# ECM3532 register map
Vendor: EtaCompute; Series: ECM35xx; File version: 1.0.0
CPU: CM3 r1p1, little endian, MPU, no FPU, 3 interrupt priority bits
Registers are 32-bit, read-write, reset 0x0 unless marked. A register's access mark holds for its fields unless they carry their own. Offsets are from the block's base; [hi:lo] are bit positions.

## ADC — The ADC AHB interface provides programming control of the analog to digital converter.
Base 0x50050000
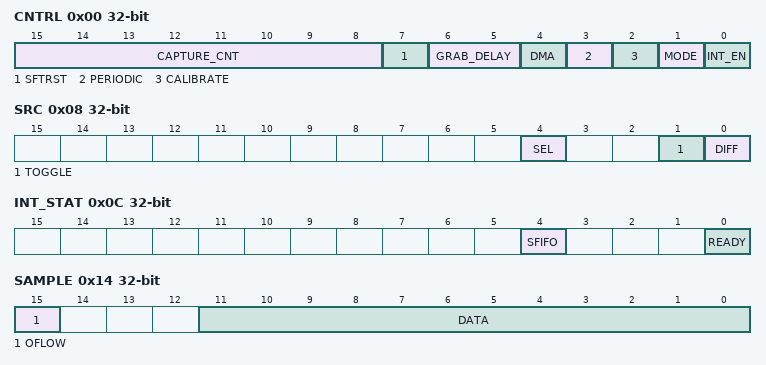
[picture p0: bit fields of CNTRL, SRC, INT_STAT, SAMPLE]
0x00 CNTRL — This register provides configuration control and status information for the ADC.
  [15:8] CAPTURE_CNT — Count for time to wait while the sample and hold circuit is sampling the signal before the conversion is started. WHile the counter continues, the trigger signal will be held low. This counter runs on a 1MHz clock.
  [7] SFTRST wo — Write a once to this bit to force a soft reset to this block.
  [6:5] GRAB_DELAY — This bit field controls whent the data from the ADC is grabbed and used.
    0=IMMED (No delay added); 1=1CLK (Delay by 1 additonal clock.); 2=2CLK (Delay by 2 additonal clocks.); 3=3CLK (Delay by 3 additonal clocks.)
  [4] DMA — Set this bit to one to enable the transfer of data over to the DSP for DMA access.
    0=DISABLE (No DSP transfers are generated.); 1=ENABLE (DSP transfers are generated.)
  [3] PERIODIC — Set this bit to one to enable periodic sampling instead of firmware triggered one shot samples.
    0=DISABLE (No periodic clock selected. Use firmware trigger register.); 1=ENABLE (Use selected periodic clock from input port to trigger a conversion cycle.)
  [2] CALIBRATE — Set to one to enable calibration mode. Essentilly the differential inputs are tied together so that the offset voltage as expressed a digital ADC count can be measure by firmware. A number of conversions should be performed and the results should be averaged. NOTE: once the calibration offset has been measured, the computed value is subtracted from each successive sample after firmware reads the value in from the ADC. This is accomplished by writing the average offset value to the OFFSET register. Hardware performs a saturated add of the offset. A further NOTE, the calibration controls are ahead of the sample and hold circuit so turn it off before attempting to capture any input into the sample and hold that you intend to convert and use.
    0=OFF (Calibration mode disabled. This is the normal operating mode.); 1=ON (Calibration mode on. Essentially the differential inputs are shorted together to measure offset voltage.)
  [1] MODE — Set to one to enable the the ADC to operate and perform captures and conversions. Set to zero to disable this block.
    0=SLEEP (ADC interface disabled and in lowest power state. NOTE the ADC voltage plain may still be on.); 1=RUN (Enable the normal operation of the ADC block.)
  [0] INT_EN — Set to one to enable interrupts to the NVIC. Interrupts will then be asserted when INT_STAT is a one.
    0=DISABLE (ADC interrupts are disabled and can't reach the NVIC.); 1=ENABLE (ADC interrupts are enabled and if they occur they will be routed to the NVIC.)
0x04 CLOCK_DIV — Clock divider register.
  [19:0] VALUE — Divider for the 1 MHz input clock. When the divider count reaches zero, it is reloaded and an ADC conversion is triggered.
0x08 SRC — This register controls the source mux and differential configurations for the ADC.
  [4] SEL — Sets the channel selector for the analog mux.
    0=CHAN0 (Channel #0); 1=CHAN1 (Channel #1)
  [1] TOGGLE — Selects the analog channel based on the state of the ADC TOGGLE register instead of the SOURCE MUX SELECT.
    1=TOGGLE (Use ADC TOGGLE as source for selector.); 0=REGISTER (Use SOURCE MUX SELECT as source for selector.)
  [0] DIFF — Set this bit to 1 for differential source pair.
    1=ENABLE (Enabled.); 0=DISABLE (Disabled.)
0x0C INT_STAT — This register contains the one interrupt status bit
  [4] SFIFO — Set to one when the SFIFO is greater the configured low marker. Write a one to this register to clear the interrupt status bit.
  [0] READY — Set to one when a conversion is complete and data is ready to read from the SAMPLE register. Write a one to this register to clear the interrupt status bit.
0x10 START — Writing anything to this register initiates the capture and conversion of an analog sample. When an ADC conversion is started, the state machine lowers the trigger pin for the required sample time. It then raises the trigger signal and resets this bit. NOTE: this register is not used in periodic mode. In that case, a trigger is automatically generated from the periodic counter.
  [7:0] NOW wo — Write anything to this bit field to start a conversion. This bit is essentially part of the state machine and is implemented over there. Once written it will read back as a one until the end of the sample period when the conversion is started. Once the hold and conversion portion of the ADC operation is begun this bit is cleared back to 0.
0x14 SAMPLE — This register returns the results of one analog to digital conversion. Reading this register as a 16-bit halfword gives access to the sample value and a single overflow indication bit.
  [15] OFLOW ro — If this bit field returns a value of 1, then an overflow occured in analog, or in the digital processing. The offset value can also cause an overflow. One can examine the RAW sample in the DEBUGB register for exact details on an overflow condition, if necessary. NOTE: This report must be enabled in the configuration register to be seeen here.
  [11:0] DATA ro — This bit field returns the post processed 12-bit ADC sample. The post processing improves the ENOB.
0x18 OFFSET — This register holds the signed 12 bit value (really 13 bits) that will be added to the 12 bit corrected value before presenting it to the user in the sample register. Be sure to clear this register before attempting to measure the offset in calibration mode. The results of adding this value to the corrected value will be saturated at both 0xFFF and 0x000. No unexpected wrapping from high to low or low to high ADC values will occur when correcting the offset.
  [12:0] VALUE — Once the offset value is determined in calibration mode, set the negative value of that offset into this 13 bit bit field. The MSB is a sign bit.
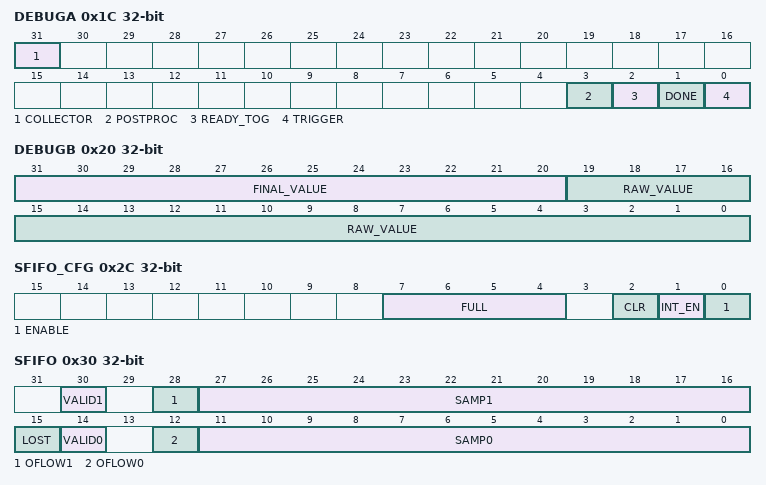
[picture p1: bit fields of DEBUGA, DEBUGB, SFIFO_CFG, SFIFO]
0x1C DEBUGA — This register provides read and write access to debug and diagnostic information.
  [31] COLLECTOR ro — This read only bit solves a synthesis problem by collecting some automatically generated signals into one load.
  [3] POSTPROC — Set this bit to one to enable the 12 bit post processed conversion information, the ADC start signal, and the ADC done signal directly to chip pads for testing. The 12 bit post processed value is output instead of the 20 bit raw value.
  [2] READY_TOG ro — This bit provides a read only view of the data ready toggled signal for the DSP.
  [1] DONE ro — Read only view of the conversion completion (DONE) signal from the analog side.
  [0] TRIGGER ro — Read only view of the trigger signal which goes low to capture the sample in the sample and hold and goes back high to trigger a conversion.
0x20 DEBUGB — This register provides read only access to debug and diagnostic information.
  [31:20] FINAL_VALUE ro — This bit field returns the post processed 12-bit ADC sample. The post processing improves the ENOB.
  [19:0] RAW_VALUE ro — Read only view of the raw 20 bit conversion result. If a single conversion is performed then this value will show the results of that last conversion.
0x24 DEBUGC — This register provides read only access to debug and diagnostic information.
  [19:0] PERIODIC_CNT ro — Shows the current value of the periodic counter.
0x28 DBG_READ_ONLY — This register provides a read only test value for checking IP connectivity to AHB.
  [31:0] VALUE ro — Shows the current value of the periodic counter.
0x2C SFIFO_CFG — Configuration register for the sample FIFO.
  [7:4] FULL — Set the level above which the sample FIFO will trigger an interrupt.
  [2] CLR wo — Set this bit to clear the SFIFO.
  [1] INT_EN — Enable the sample FIFO full interrupt.
  [0] ENABLE — Set this bit to enable the SFIFO.
0x30 SFIFO — WARNING: READ SIDE EFFECT.This register provides a read interface for the sample FIFO. A 32-bit read pops a maximum of two samples off the FIFO. A 16-bit read to the lower half of the register pops one sample off the FIFO. An 8-bit read does nothing. Check the associated VALID bit to know if a SAMP field contains a valid sample.
  [30] VALID1 ro — Indicates whether SAMP1 contains valid data.
  [28] OFLOW1 ro — Overflow bit for SAMP1.
  [27:16] SAMP1 ro — The value of the second sample out of the FIFO.
  [15] LOST ro — Indicates whether at least one sample was lost due to FIFO overflow.
  [14] VALID0 ro — Indicates whether SAMP0 contains valid data.
  [12] OFLOW0 ro — Overflow bit for SAMP0.
  [11:0] SAMP0 ro — The value of the first sample out of the FIFO.
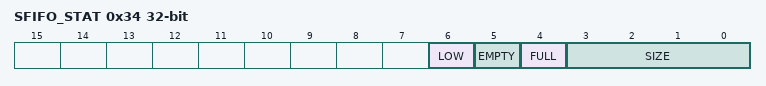
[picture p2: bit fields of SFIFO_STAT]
0x34 SFIFO_STAT — Status register for the sample FIFO.
  [6] LOW ro — Indicates if the size of the sample FIFO is above the SFIFO_CFG_FULL interrupt level.
    1=LOW
  [5] EMPTY ro — Indicates if the sample FIFO is empty.
    1=EMPTY
  [4] FULL ro — Indicates if the sample FIFO is full.
    1=FULL
  [3:0] SIZE ro — Current consumption of the sample FIFO from 0 -> 15. Check FULL to see if consumption is 16.
0x38 TOGGLE — When in periodic mode the ADC toggle register toggles halfway through every period. This register can be driven on CLKOUT or used to select the source of the internal analog MUX. See the CLKOUT register in the RTC register file or the TOGGLE bit of the SRC register respectively.
  [0] STATE — The current state of the ADC toggle register. Can be written with an initial value.
